# ESP32 register map
Vendor: ESPRESSIF SYSTEMS (SHANGHAI) CO., LTD.; Series: ESP32 Series; File version: 17
CPU: Xtensa LX6 r0p0, little endian, no MPU, FPU, 0 interrupt priority bits
Address unit: 32 bits
Registers are 32-bit, read-write, reset 0x0 unless marked. A register's access mark holds for its fields unless they carry their own. Offsets are from the block's base; [hi:lo] are bit positions; {n}, {i} and the like mark numbered series.

## PCNT — Pulse Count Controller
Base 0x3FF57000
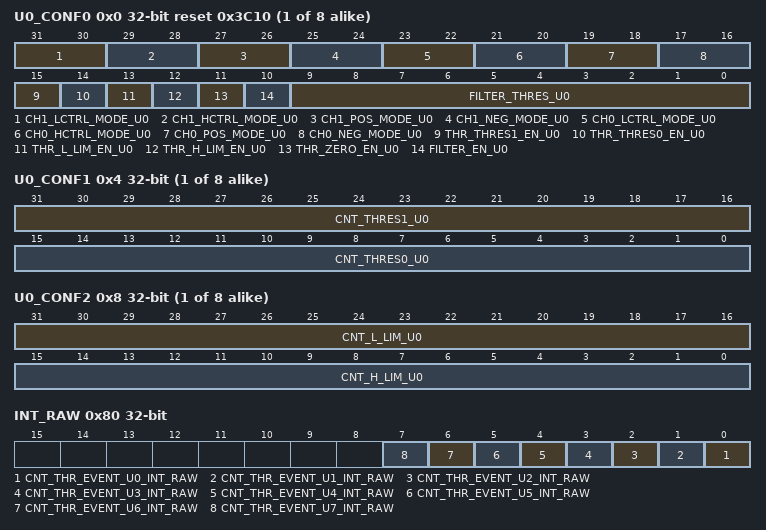
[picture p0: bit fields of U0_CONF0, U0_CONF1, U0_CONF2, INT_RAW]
{0x0+0xC*i} U{i}_CONF0 reset 0x3C10 (i=0..7)
  [31:30] CH1_LCTRL_MODE_U{i} — This register is used to control the mode of channel1's low control signal for unit{i}. 2'd0:increase when control signal is low 2'd1: decrease when control signal is high others:forbidden
  [29:28] CH1_HCTRL_MODE_U{i} — This register is used to control the mode of channel1's high control signal for unit{i}. 2'd0:increase when control signal is low 2'd1: decrease when control signal is high others:forbidden
  [27:26] CH1_POS_MODE_U{i} — This register is used to control the mode of channel1's input posedge signal for unit{i}. 2'd1: increase at the posedge of input signal 2'd2:decrease at the posedge of input signal others:forbidden
  [25:24] CH1_NEG_MODE_U{i} — This register is used to control the mode of channel1's input negedge signal for unit{i}. 2'd1: increase at the negedge of input signal 2'd2:decrease at the negedge of input signal others:forbidden
  [23:22] CH0_LCTRL_MODE_U{i} — This register is used to control the mode of channel0's low control signal for unit{i}. 2'd0:increase when control signal is low 2'd1: decrease when control signal is high others:forbidden
  [21:20] CH0_HCTRL_MODE_U{i} — This register is used to control the mode of channel0's high control signal for unit{i}. 2'd0:increase when control signal is low 2'd1: decrease when control signal is high others:forbidden
  [19:18] CH0_POS_MODE_U{i} — This register is used to control the mode of channel0's input posedge signal for unit{i}. 2'd1: increase at the posedge of input signal 2'd2:decrease at the posedge of input signal others:forbidden
  [17:16] CH0_NEG_MODE_U{i} — This register is used to control the mode of channel0's input negedge signal for unit{i}. 2'd1: increase at the negedge of input signal 2'd2:decrease at the negedge of input signal others:forbidden
  [15] THR_THRES1_EN_U{i} — This is the enable bit for comparing unit{i}'s count with thres1 value .
  [14] THR_THRES0_EN_U{i} — This is the enable bit for comparing unit{i}'s count with thres0 value.
  [13] THR_L_LIM_EN_U{i} — This is the enable bit for comparing unit{i}'s count with thr_l_lim value.
  [12] THR_H_LIM_EN_U{i} — This is the enable bit for comparing unit{i}'s count with thr_h_lim value.
  [11] THR_ZERO_EN_U{i} — This is the enable bit for comparing unit{i}'s count with 0 value.
  [10] FILTER_EN_U{i} — This is the enable bit for filtering input signals for unit{i}.
  [9:0] FILTER_THRES_U{i} — This register is used to filter pluse whose width is smaller than this value for unit{i}.
{0x4+0xC*i} U{i}_CONF1 (i=0..7)
  [31:16] CNT_THRES1_U{i} — This register is used to configure thres1 value for unit{i}.
  [15:0] CNT_THRES0_U{i} — This register is used to configure thres0 value for unit{i}.
{0x8+0xC*i} U{i}_CONF2 (i=0..7)
  [31:16] CNT_L_LIM_U{i} — This register is used to confiugre thr_l_lim value for unit{i}.
  [15:0] CNT_H_LIM_U{i} — This register is used to configure thr_h_lim value for unit{i}.
{0x60+4i} U{i}_CNT ro (i=0..7)
  [15:0] PLUS_CNT_U{i} — This register stores the current pulse count value for unit{i}.
0x80 INT_RAW ro
  [n] CNT_THR_EVENT_U{n}_INT_RAW (n=0..7) — This is the interrupt raw bit for channel{n} event.
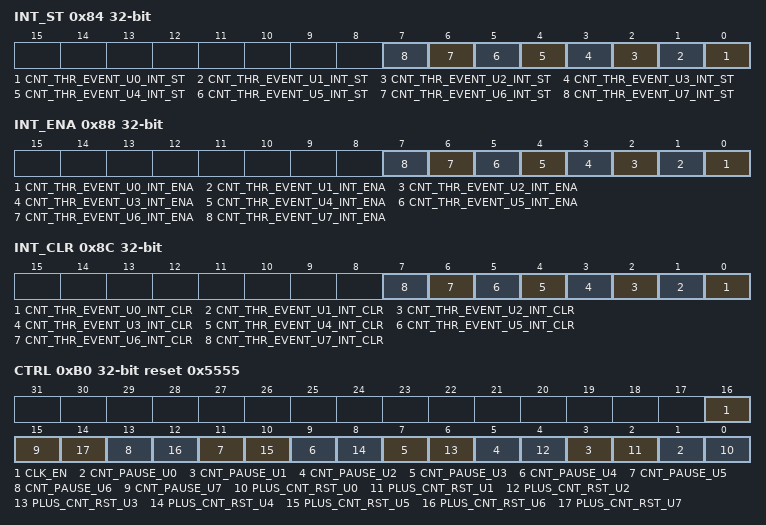
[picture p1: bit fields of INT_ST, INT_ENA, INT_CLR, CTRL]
0x84 INT_ST ro
  [n] CNT_THR_EVENT_U{n}_INT_ST (n=0..7) — This is the interrupt status bit for channel{n} event.
0x88 INT_ENA
  [n] CNT_THR_EVENT_U{n}_INT_ENA (n=0..7) — This is the interrupt enable bit for channel{n} event.
0x8C INT_CLR wo
  [n] CNT_THR_EVENT_U{n}_INT_CLR (n=0..7) — Set this bit to clear channel{n} event interrupt.
0x90 U0_STATUS access per field
  [6] STATUS_ZERO rw, [5] STATUS_H_LIM rw, [4] STATUS_L_LIM rw, [3] STATUS_THRES0 rw, [2] STATUS_THRES1 rw, [31:0] CORE_STATUS_U0 ro, [1:0] STATUS_CNT_MODE rw
{0x90+4i} U{i}_STATUS ro (i=1..7)
  [31:0] CORE_STATUS_U{i}
0xB0 CTRL reset 0x5555
  [16] CLK_EN
  [2n+1] CNT_PAUSE_U{n} (n=0..7) — Set this bit to pause unit{n}'s counter.
  [2n] PLUS_CNT_RST_U{n} (n=0..7) — Set this bit to clear unit{n}'s counter.
0xFC DATE reset 0x14122600
